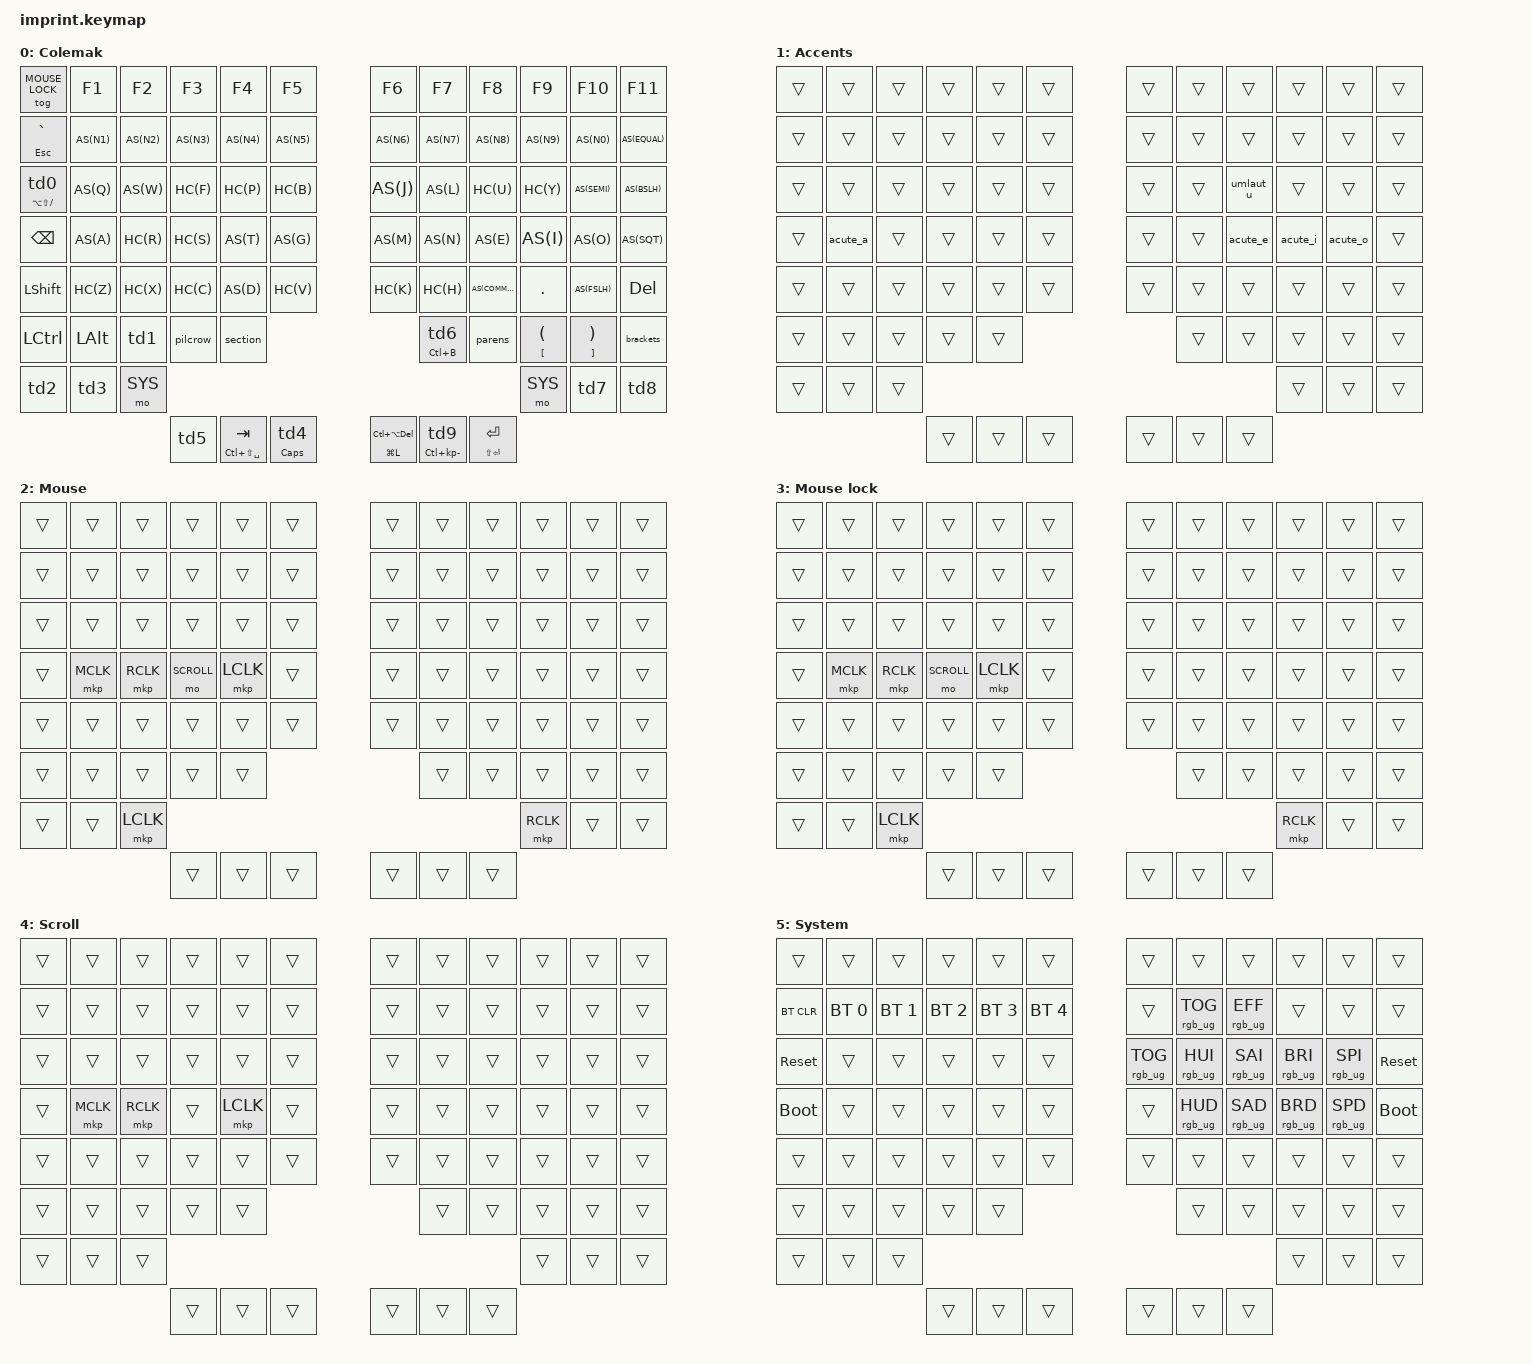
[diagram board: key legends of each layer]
/*
 * Cyboard Imprint (function row, 5-key bottom row, trackball on the right half)
 *
 * Ported from Benedict's ErgoDox EZ "Colemak U.S. legal writing" Oryx layout
 * (QMK). Colemak-DH alphas, Ctrl-on-hold letter keys, tap dances, auto shift,
 * Word accent/symbol macros, and the accent layer all carry over.
 *
 * Key positions (82 keys) for physical_layout_imprint_function_row_full_bottom_row:
 *
 *   0  1  2  3  4  5          6  7  8  9 10 11     function row
 *  12 13 14 15 16 17         18 19 20 21 22 23     number row
 *  24 25 26 27 28 29         30 31 32 33 34 35     top letter row
 *  36 37 38 39 40 41         42 43 44 45 46 47     home row
 *  48 49 50 51 52 53         54 55 56 57 58 59     bottom letter row
 *  60 61 62 63 64               65 66 67 68 69     5-key bottom row
 *                70 71 72   73 74 75               thumb arc 1 (70 / 75 nearest the letters)
 *                76 77 78   79 80 81               thumb arc 2
 */

#include <input/processors.dtsi>
#include <dt-bindings/zmk/input_transform.h>
#include <behaviors.dtsi>
#include <dt-bindings/zmk/bt.h>
#include <dt-bindings/zmk/keys.h>
#include <dt-bindings/zmk/pointing.h>
#include <dt-bindings/zmk/rgb.h>

#define BASE   0
#define ACCENT 1
#define MOUSE  2
#define MOUSE_LOCK 3
#define SCROLL 4
#define SYS    5

// ErgoDox TAPPING_TERM was 198 ms; QMK's default auto shift timeout is 175 ms.
#define TAPPING_TERM 198
#define AUTO_SHIFT_TIMEOUT 175

// Auto shift: tap for the key, hold past AUTO_SHIFT_TIMEOUT for its shifted
// version. To turn auto shift off, change this line to: #define AS(k) &kp k
#define AS(k) &as LS(k) k

// Tap for the key, hold for Ctrl+key (the ErgoDox "dual function" keys).
#define HC(k) &ht LC(k) k

/ {
    chosen { zmk,physical-layout = &physical_layout_imprint_function_row_full_bottom_row; };

    behaviors {
        // Generic tap/hold key: &ht <hold> <tap>.
        ht: hold_tap {
            compatible = "zmk,behavior-hold-tap";
            #binding-cells = <2>;
            flavor = "tap-preferred";
            tapping-term-ms = <TAPPING_TERM>;
            quick-tap-ms = <TAPPING_TERM>;
            bindings = <&kp>, <&kp>;
        };

        // Auto shift: &as <shifted> <key>.
        as: auto_shift {
            compatible = "zmk,behavior-hold-tap";
            #binding-cells = <2>;
            flavor = "tap-preferred";
            tapping-term-ms = <AUTO_SHIFT_TIMEOUT>;
            bindings = <&kp>, <&kp>;
        };

        // Tap sends the key twice, hold sends another key: &ht_dbl <hold> <key>.
        // Used for the "double tap / double hold" slot of the arrow and space dances.
        ht_dbl: hold_tap_double {
            compatible = "zmk,behavior-hold-tap";
            #binding-cells = <2>;
            flavor = "tap-preferred";
            tapping-term-ms = <TAPPING_TERM>;
            bindings = <&kp>, <&dbl>;
        };

        // DANCE_0: tap Ctrl+Shift+/, hold Alt+Shift+/, double tap _
        td0: tap_dance_0 {
            compatible = "zmk,behavior-tap-dance";
            #binding-cells = <0>;
            tapping-term-ms = <TAPPING_TERM>;
            bindings = <&kp LC(LS(FSLH))>, <&kp UNDERSCORE>;
        };
        td0_ht: tap_dance_0_hold {
            compatible = "zmk,behavior-hold-tap";
            #binding-cells = <2>;
            flavor = "tap-preferred";
            tapping-term-ms = <TAPPING_TERM>;
            bindings = <&kp>, <&td0>;
        };

        // DANCE_1: tap/hold GUI, double tap toggles the accent layer
        td1: tap_dance_1 {
            compatible = "zmk,behavior-tap-dance";
            #binding-cells = <0>;
            tapping-term-ms = <TAPPING_TERM>;
            bindings = <&kp LGUI>, <&tog ACCENT>;
        };

        // DANCE_2: Up, double tap Up Up, double tap-and-hold Page Up
        td2: tap_dance_2 {
            compatible = "zmk,behavior-tap-dance";
            #binding-cells = <0>;
            tapping-term-ms = <TAPPING_TERM>;
            bindings = <&kp UP>, <&ht_dbl PG_UP UP>;
        };

        // DANCE_3: Down, double tap Down Down, double tap-and-hold Page Down
        td3: tap_dance_3 {
            compatible = "zmk,behavior-tap-dance";
            #binding-cells = <0>;
            tapping-term-ms = <TAPPING_TERM>;
            bindings = <&kp DOWN>, <&ht_dbl PG_DN DOWN>;
        };

        // DANCE_4: tap Num Lock, hold Caps Lock, double tap Ctrl+Shift+A (Word all caps)
        td4: tap_dance_4 {
            compatible = "zmk,behavior-tap-dance";
            #binding-cells = <0>;
            tapping-term-ms = <TAPPING_TERM>;
            bindings = <&kp KP_NUM>, <&kp LC(LS(A))>;
        };
        td4_ht: tap_dance_4_hold {
            compatible = "zmk,behavior-hold-tap";
            #binding-cells = <2>;
            flavor = "tap-preferred";
            tapping-term-ms = <TAPPING_TERM>;
            bindings = <&kp>, <&td4>;
        };

        // DANCE_5: Space, double tap two spaces, double tap-and-hold Ctrl+Alt+Shift+Space
        td5: tap_dance_5 {
            compatible = "zmk,behavior-tap-dance";
            #binding-cells = <0>;
            tapping-term-ms = <TAPPING_TERM>;
            bindings = <&kp SPACE>, <&ht_dbl LC(LA(LS(SPACE))) SPACE>;
        };

        // DANCE_6: tap Ctrl+I, hold Ctrl+B, double tap Ctrl+U
        td6: tap_dance_6 {
            compatible = "zmk,behavior-tap-dance";
            #binding-cells = <0>;
            tapping-term-ms = <TAPPING_TERM>;
            bindings = <&kp LC(I)>, <&kp LC(U)>;
        };
        td6_ht: tap_dance_6_hold {
            compatible = "zmk,behavior-hold-tap";
            #binding-cells = <2>;
            flavor = "tap-preferred";
            tapping-term-ms = <TAPPING_TERM>;
            bindings = <&kp>, <&td6>;
        };

        // DANCE_7: Left, double tap Left Left, double tap-and-hold Home
        td7: tap_dance_7 {
            compatible = "zmk,behavior-tap-dance";
            #binding-cells = <0>;
            tapping-term-ms = <TAPPING_TERM>;
            bindings = <&kp LEFT>, <&ht_dbl HOME LEFT>;
        };

        // DANCE_8: Right, double tap Right Right, double tap-and-hold End
        td8: tap_dance_8 {
            compatible = "zmk,behavior-tap-dance";
            #binding-cells = <0>;
            tapping-term-ms = <TAPPING_TERM>;
            bindings = <&kp RIGHT>, <&ht_dbl END RIGHT>;
        };

        // DANCE_9: tap -, hold Ctrl+keypad -, double tap Ctrl+Alt+- (Word em dash)
        td9: tap_dance_9 {
            compatible = "zmk,behavior-tap-dance";
            #binding-cells = <0>;
            tapping-term-ms = <TAPPING_TERM>;
            bindings = <&kp MINUS>, <&kp LC(LA(MINUS))>;
        };
        td9_ht: tap_dance_9_hold {
            compatible = "zmk,behavior-hold-tap";
            #binding-cells = <2>;
            flavor = "tap-preferred";
            tapping-term-ms = <TAPPING_TERM>;
            bindings = <&kp>, <&td9>;
        };
    };

    macros {
        // Taps its key twice.
        dbl: double_tap {
            compatible = "zmk,behavior-macro-one-param";
            #binding-cells = <1>;
            bindings
                = <&macro_param_1to1>, <&macro_tap &kp MACRO_PLACEHOLDER>
                , <&macro_param_1to1>, <&macro_tap &kp MACRO_PLACEHOLDER>
                ;
        };

        // ST_MACRO_0: Alt+20 on the keypad (Windows alt code for the pilcrow)
        pilcrow: pilcrow {
            compatible = "zmk,behavior-macro";
            #binding-cells = <0>;
            wait-ms = <100>;
            bindings
                = <&macro_press &kp LALT>
                , <&macro_tap &kp KP_N2 &kp KP_N0>
                , <&macro_release &kp LALT>
                ;
        };

        // ST_MACRO_1: Alt+21 on the keypad (Windows alt code for the section sign)
        section: section {
            compatible = "zmk,behavior-macro";
            #binding-cells = <0>;
            wait-ms = <100>;
            bindings
                = <&macro_press &kp LALT>
                , <&macro_tap &kp KP_N2 &kp KP_N1>
                , <&macro_release &kp LALT>
                ;
        };

        // ST_MACRO_2: () with the cursor between them
        parens: parens {
            compatible = "zmk,behavior-macro";
            #binding-cells = <0>;
            wait-ms = <100>;
            bindings = <&macro_tap &kp LPAR &kp RPAR &kp LEFT>;
        };

        // ST_MACRO_3: [] with the cursor between them
        brackets: brackets {
            compatible = "zmk,behavior-macro";
            #binding-cells = <0>;
            wait-ms = <100>;
            bindings = <&macro_tap &kp LBKT &kp RBKT &kp LEFT>;
        };

        // ST_MACRO_4, 6, 7, 8: Word acute accent (Ctrl+' then the vowel)
        acute_a: acute_a {
            compatible = "zmk,behavior-macro";
            #binding-cells = <0>;
            wait-ms = <100>;
            bindings = <&macro_tap &kp LC(SQT) &kp A>;
        };
        acute_e: acute_e {
            compatible = "zmk,behavior-macro";
            #binding-cells = <0>;
            wait-ms = <100>;
            bindings = <&macro_tap &kp LC(SQT) &kp E>;
        };
        acute_i: acute_i {
            compatible = "zmk,behavior-macro";
            #binding-cells = <0>;
            wait-ms = <100>;
            bindings = <&macro_tap &kp LC(SQT) &kp I>;
        };
        acute_o: acute_o {
            compatible = "zmk,behavior-macro";
            #binding-cells = <0>;
            wait-ms = <100>;
            bindings = <&macro_tap &kp LC(SQT) &kp O>;
        };

        // ST_MACRO_5: Word umlaut (Ctrl+Shift+; then u)
        umlaut_u: umlaut_u {
            compatible = "zmk,behavior-macro";
            #binding-cells = <0>;
            wait-ms = <100>;
            bindings = <&macro_tap &kp LC(LS(SEMI)) &kp U>;
        };
    };

    // Auto mouse layer for the right trackball: moving the ball turns on the
    // MOUSE layer until the ball has been still for 10 seconds. It is not turned
    // on if a key was pressed in the last 150 ms, so brushing the ball while
    // typing doesn't swallow letters. Pressing any key other than the click keys
    // (thumb keys 72 and 73 included), the scroll key, and the modifiers turns it
    // off sooner.
    zip_mouse_layer: zip_mouse_layer {
        compatible = "zmk,input-processor-temp-layer";
        #input-processor-cells = <2>;
        require-prior-idle-ms = <150>;
        excluded-positions = <37 38 39 40 48 60 61 62 72 73>;
    };

    keymap {
        compatible = "zmk,keymap";

        base_layer {
            display-name = "Colemak";
            bindings = <
&tog MOUSE_LOCK &kp F1       &kp F2       &kp F3     &kp F4     &kp F5                             &kp F6      &kp F7          &kp F8         &kp F9          &kp F10         &kp F11
&ht ESC GRAVE   AS(N1)       AS(N2)       AS(N3)     AS(N4)     AS(N5)                             AS(N6)      AS(N7)          AS(N8)         AS(N9)          AS(N0)          AS(EQUAL)
&td0_ht LA(LS(FSLH)) 0       AS(Q)        AS(W)      HC(F)      HC(P)      HC(B)                   AS(J)       AS(L)           HC(U)          HC(Y)           AS(SEMI)        AS(BSLH)
&kp BSPC        AS(A)        HC(R)        HC(S)      AS(T)      AS(G)                              AS(M)       AS(N)           AS(E)          AS(I)           AS(O)           AS(SQT)
&kp LSHFT       HC(Z)        HC(X)        HC(C)      AS(D)      HC(V)                              HC(K)       HC(H)           AS(COMMA)      &kp DOT         AS(FSLH)        &kp DEL
&kp LCTRL       &kp LALT     &td1         &pilcrow   &section                                                  &td6_ht LC(B) 0 &parens        &ht LBKT LPAR   &ht RBKT RPAR   &brackets
                                                     &td2       &td3                   &mo SYS                 &mo SYS                &td7                    &td8
                                                     &td5       &ht LC(LS(SPACE)) TAB  &td4_ht CAPS 0          &ht LG(L) LC(LA(DEL))  &td9_ht LC(KP_MINUS) 0  &ht LS(RET) RET
            >;
        };

        accent_layer {
            display-name = "Accents";
            bindings = <
&trans  &trans    &trans  &trans  &trans  &trans            &trans  &trans  &trans     &trans    &trans    &trans
&trans  &trans    &trans  &trans  &trans  &trans            &trans  &trans  &trans     &trans    &trans    &trans
&trans  &trans    &trans  &trans  &trans  &trans            &trans  &trans  &umlaut_u  &trans    &trans    &trans
&trans  &acute_a  &trans  &trans  &trans  &trans            &trans  &trans  &acute_e   &acute_i  &acute_o  &trans
&trans  &trans    &trans  &trans  &trans  &trans            &trans  &trans  &trans     &trans    &trans    &trans
&trans  &trans    &trans  &trans  &trans                            &trans  &trans     &trans    &trans    &trans
                                  &trans  &trans  &trans    &trans  &trans  &trans
                                  &trans  &trans  &trans    &trans  &trans  &trans
            >;
        };

        mouse_layer {
            display-name = "Mouse";
            bindings = <
&trans  &trans      &trans     &trans     &trans     &trans            &trans  &trans  &trans  &trans  &trans  &trans
&trans  &trans      &trans     &trans     &trans     &trans            &trans  &trans  &trans  &trans  &trans  &trans
&trans  &trans      &trans     &trans     &trans     &trans            &trans  &trans  &trans  &trans  &trans  &trans
&trans  &mkp MCLK   &mkp RCLK  &mo SCROLL &mkp LCLK  &trans            &trans  &trans  &trans  &trans  &trans  &trans
&trans  &trans      &trans     &trans     &trans     &trans            &trans  &trans  &trans  &trans  &trans  &trans
&trans  &trans      &trans     &trans     &trans                               &trans  &trans  &trans  &trans  &trans
                                          &trans     &trans  &mkp LCLK &mkp RCLK  &trans  &trans
                                          &trans     &trans  &trans    &trans  &trans  &trans
            >;
        };

        // Same keys as the Mouse layer, but turned on and off with key 0 instead of
        // by the trackball, so neither typing nor a still ball switches it off.
        mouse_lock_layer {
            display-name = "Mouse lock";
            bindings = <
&trans  &trans      &trans     &trans     &trans     &trans            &trans  &trans  &trans  &trans  &trans  &trans
&trans  &trans      &trans     &trans     &trans     &trans            &trans  &trans  &trans  &trans  &trans  &trans
&trans  &trans      &trans     &trans     &trans     &trans            &trans  &trans  &trans  &trans  &trans  &trans
&trans  &mkp MCLK   &mkp RCLK  &mo SCROLL &mkp LCLK  &trans            &trans  &trans  &trans  &trans  &trans  &trans
&trans  &trans      &trans     &trans     &trans     &trans            &trans  &trans  &trans  &trans  &trans  &trans
&trans  &trans      &trans     &trans     &trans                               &trans  &trans  &trans  &trans  &trans
                                          &trans     &trans  &mkp LCLK &mkp RCLK  &trans  &trans
                                          &trans     &trans  &trans    &trans  &trans  &trans
            >;
        };

        scroll_layer {
            display-name = "Scroll";
            bindings = <
&trans  &trans  &trans     &trans     &trans     &trans            &trans  &trans  &trans  &trans  &trans  &trans
&trans  &trans  &trans     &trans     &trans     &trans            &trans  &trans  &trans  &trans  &trans  &trans
&trans  &trans  &trans     &trans     &trans     &trans            &trans  &trans  &trans  &trans  &trans  &trans
&trans  &mkp MCLK  &mkp RCLK  &trans  &mkp LCLK  &trans            &trans  &trans  &trans  &trans  &trans  &trans
&trans  &trans  &trans     &trans     &trans     &trans            &trans  &trans  &trans  &trans  &trans  &trans
&trans  &trans  &trans     &trans     &trans                               &trans  &trans  &trans  &trans  &trans
                                      &trans     &trans  &trans    &trans  &trans  &trans
                                      &trans     &trans  &trans    &trans  &trans  &trans
            >;
        };

        system_layer {
            display-name = "System";
            bindings = <
&trans       &trans        &trans        &trans        &trans        &trans                  &trans           &trans           &trans           &trans           &trans           &trans
&bt BT_CLR   &bt BT_SEL 0  &bt BT_SEL 1  &bt BT_SEL 2  &bt BT_SEL 3  &bt BT_SEL 4            &trans           &rgb_ug RGB_TOG  &rgb_ug RGB_EFF  &trans           &trans           &trans
&sys_reset   &trans        &trans        &trans        &trans        &trans                  &rgb_ug RGB_TOG  &rgb_ug RGB_HUI  &rgb_ug RGB_SAI  &rgb_ug RGB_BRI  &rgb_ug RGB_SPI  &sys_reset
&bootloader  &trans        &trans        &trans        &trans        &trans                  &trans           &rgb_ug RGB_HUD  &rgb_ug RGB_SAD  &rgb_ug RGB_BRD  &rgb_ug RGB_SPD  &bootloader
&trans       &trans        &trans        &trans        &trans        &trans                  &trans           &trans           &trans           &trans           &trans           &trans
&trans       &trans        &trans        &trans        &trans                                                 &trans           &trans           &trans           &trans           &trans
                                                       &trans        &trans        &trans    &trans           &trans           &trans
                                                       &trans        &trans        &trans    &trans           &trans           &trans
            >;
        };
    };
};

// Right-hand trackball: cursor by default, auto mouse layer once it moves,
// and scrolling while the Scroll key (S position on the Mouse layer) is held.
&trackball_peripheral_listener {
    input-processors = <&zip_mouse_layer MOUSE 10000>;

    scroller {
        layers = <SCROLL>;
        input-processors =
            // slow it down for scrolling, as in Cyboard's stock config
            <&zip_xy_scaler 1 3>,
            <&zip_xy_to_scroll_mapper>,
            // the view moves the same way as the top of the ball
            <&zip_scroll_transform INPUT_TRANSFORM_Y_INVERT>;
    };
};
